VERSION ""

NS_ :

BS_:

BU_: XXX

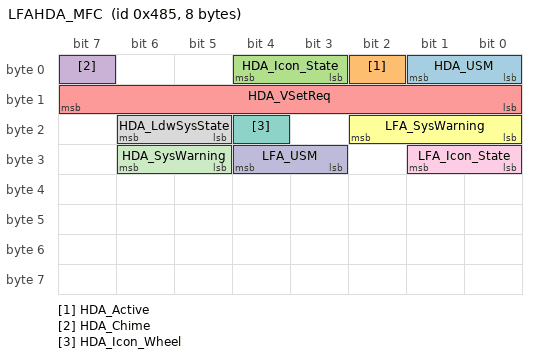
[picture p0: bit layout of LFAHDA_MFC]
BO_ 1157 LFAHDA_MFC: 8 XXX
 SG_ HDA_USM : 0|2@1+ (1,0) [0|3] "" XXX
 SG_ HDA_Active : 2|1@1+ (1,0) [0|1] "" XXX
 SG_ HDA_Icon_State : 3|2@1+ (1,0) [0|3] "" XXX
 SG_ HDA_Chime : 7|1@1+ (1,0) [0|1] "" XXX
 SG_ HDA_VSetReq : 8|8@1+ (1,0) [0|255] "km/h" XXX
 SG_ LFA_SysWarning : 16|3@1+ (1,0) [0|7] "" XXX
 SG_ HDA_Icon_Wheel : 20|1@1+ (1,0) [0|1] "" XXX
 SG_ HDA_LdwSysState : 21|2@1+ (1,0) [0|3] "" XXX
 SG_ LFA_Icon_State : 24|2@1+ (1,0) [0|3] "" XXX
 SG_ LFA_USM : 27|2@1+ (1,0) [0|3] "" XXX
 SG_ HDA_SysWarning : 29|2@1+ (1,0) [0|3] "" XXX
